# msp430g2452 register map
Registers from a debugger description file.
Registers are 8-bit, access not given, no defined reset value unless marked. A register's access mark holds for its fields unless they carry their own. Addresses are absolute; registers are grouped by the start of their names; lines under a group give offsets from that group; [hi:lo] are bit positions; {n}, {i} and the like mark numbered series; 'fields as' and 'values as' point back to an identical list; <NAME> marks a mode.

## SFR
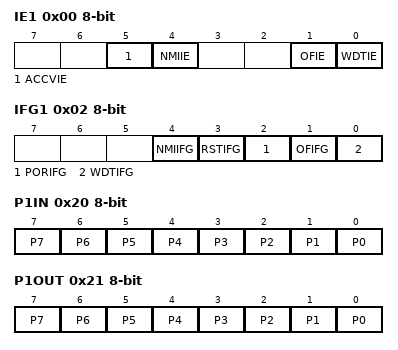
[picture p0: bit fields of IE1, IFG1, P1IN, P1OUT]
0x00 IE1
  [5] ACCVIE, [4] NMIIE, [1] OFIE, [0] WDTIE
0x02 IFG1
  [4] NMIIFG, [3] RSTIFG, [2] PORIFG, [1] OFIFG, [0] WDTIFG
0x20 P1IN
  [n] P{n} (n=0..7)
0x21 P1OUT
  [n] P{n} (n=0..7)
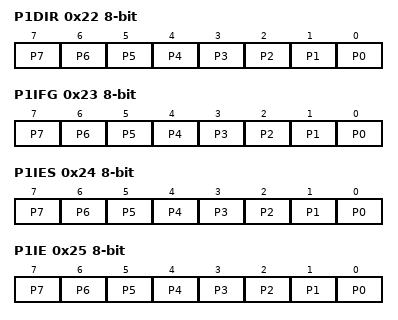
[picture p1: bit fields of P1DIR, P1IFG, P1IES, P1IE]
0x22 P1DIR
  [n] P{n} (n=0..7)
0x23 P1IFG
  [n] P{n} (n=0..7)
0x24 P1IES
  [n] P{n} (n=0..7)
0x25 P1IE
  [n] P{n} (n=0..7)
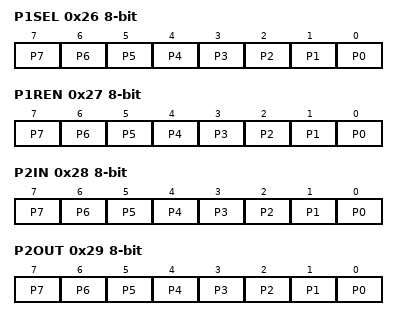
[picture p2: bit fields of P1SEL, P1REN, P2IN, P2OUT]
0x26 P1SEL
  [n] P{n} (n=0..7)
0x27 P1REN
  [n] P{n} (n=0..7)
0x28 P2IN
  [n] P{n} (n=0..7)
0x29 P2OUT
  [n] P{n} (n=0..7)
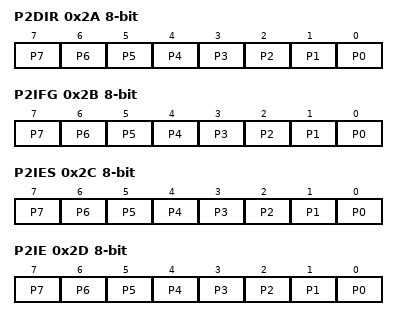
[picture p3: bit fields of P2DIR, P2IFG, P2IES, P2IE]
0x2A P2DIR
  [n] P{n} (n=0..7)
0x2B P2IFG
  [n] P{n} (n=0..7)
0x2C P2IES
  [n] P{n} (n=0..7)
0x2D P2IE
  [n] P{n} (n=0..7)
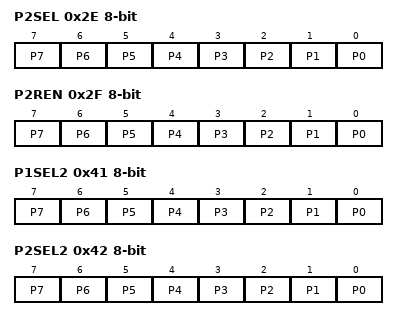
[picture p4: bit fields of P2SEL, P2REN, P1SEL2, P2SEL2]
0x2E P2SEL
  [n] P{n} (n=0..7)
0x2F P2REN
  [n] P{n} (n=0..7)
0x41 P1SEL2
  [n] P{n} (n=0..7)
0x42 P2SEL2
  [n] P{n} (n=0..7)
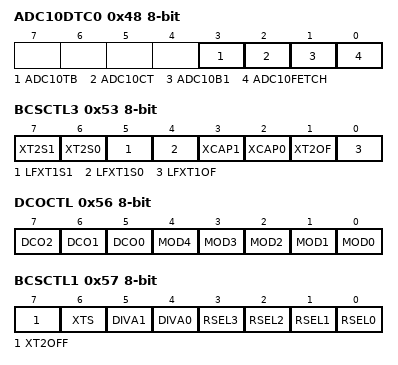
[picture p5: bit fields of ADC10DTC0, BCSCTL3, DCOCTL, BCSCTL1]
0x48 ADC10DTC0
  [3] ADC10TB, [2] ADC10CT, [1] ADC10B1, [0] ADC10FETCH
0x49 ADC10DTC1
0x4A ADC10AE0
0x53 BCSCTL3
  [7] XT2S1, [6] XT2S0, [5] LFXT1S1, [4] LFXT1S0, [3] XCAP1, [2] XCAP0, [1] XT2OF, [0] LFXT1OF
0x56 DCOCTL
  [7] DCO2, [6] DCO1, [5] DCO0, [n] MOD{n} (n=0..4)
0x57 BCSCTL1
  [7] XT2OFF, [6] XTS, [5] DIVA1, [4] DIVA0, [n] RSEL{n} (n=0..3)
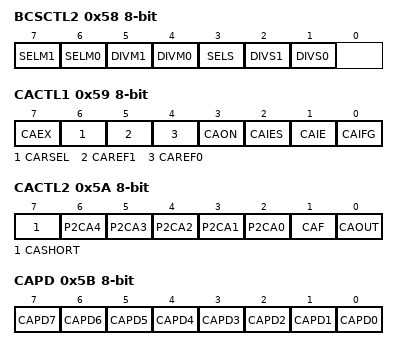
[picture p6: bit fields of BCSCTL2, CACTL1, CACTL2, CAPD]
0x58 BCSCTL2
  [7] SELM1, [6] SELM0, [5] DIVM1, [4] DIVM0, [3] SELS, [2] DIVS1, [1] DIVS0
0x59 CACTL1
  [7] CAEX, [6] CARSEL, [5] CAREF1, [4] CAREF0, [3] CAON, [2] CAIES, [1] CAIE, [0] CAIFG
0x5A CACTL2
  [7] CASHORT, [n+2] P2CA{n} (n=0..4), [1] CAF, [0] CAOUT
0x5B CAPD
  [n] CAPD{n} (n=0..7)
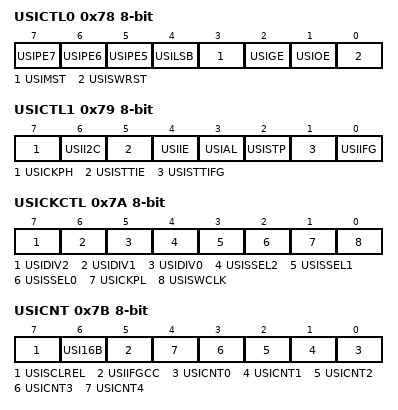
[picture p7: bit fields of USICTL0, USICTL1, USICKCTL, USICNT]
0x78 USICTL0
  [7] USIPE7, [6] USIPE6, [5] USIPE5, [4] USILSB, [3] USIMST, [2] USIGE, [1] USIOE, [0] USISWRST
0x78 USICTL 16-bit
0x79 USICTL1
  [7] USICKPH, [6] USII2C, [5] USISTTIE, [4] USIIE, [3] USIAL, [2] USISTP, [1] USISTTIFG, [0] USIIFG
0x7A USICKCTL
  [7] USIDIV2, [6] USIDIV1, [5] USIDIV0, [4] USISSEL2, [3] USISSEL1, [2] USISSEL0, [1] USICKPL, [0] USISWCLK
0x7A USICCTL 16-bit
0x7B USICNT
  [7] USISCLREL, [6] USI16B, [5] USIIFGCC, [n] USICNT{n} (n=0..4)
0x7C USISRL
0x7C USISR 16-bit
0x7D USISRH
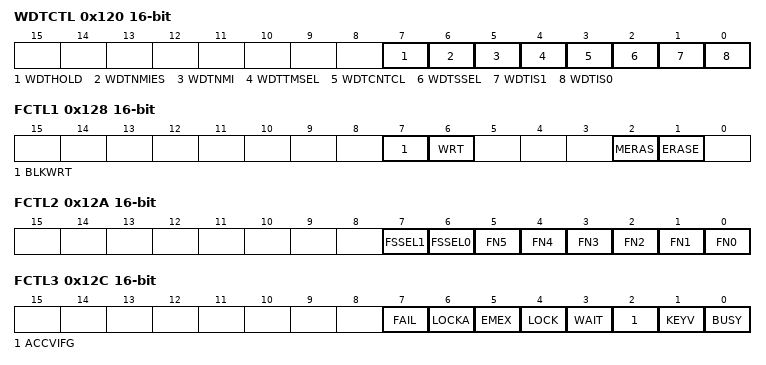
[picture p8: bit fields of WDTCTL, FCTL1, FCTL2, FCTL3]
0x120 WDTCTL 16-bit
  [7] WDTHOLD, [6] WDTNMIES, [5] WDTNMI, [4] WDTTMSEL, [3] WDTCNTCL, [2] WDTSSEL, [1] WDTIS1, [0] WDTIS0
0x128 FCTL1 16-bit
  [7] BLKWRT, [6] WRT, [2] MERAS, [1] ERASE
0x12A FCTL2 16-bit
  [7] FSSEL1, [6] FSSEL0, [n] FN{n} (n=0..5)
0x12C FCTL3 16-bit
  [7] FAIL, [6] LOCKA, [5] EMEX, [4] LOCK, [3] WAIT, [2] ACCVIFG, [1] KEYV, [0] BUSY
0x12E TA0IV 16-bit
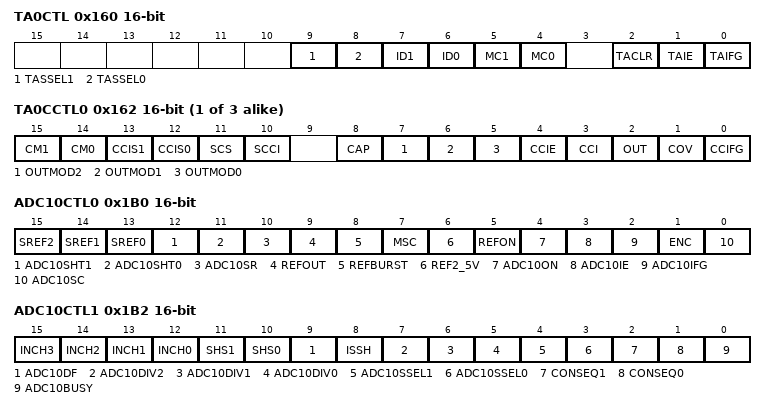
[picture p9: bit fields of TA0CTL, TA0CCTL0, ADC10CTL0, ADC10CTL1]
0x160 TA0CTL 16-bit
  [9] TASSEL1, [8] TASSEL0, [7] ID1, [6] ID0, [5] MC1, [4] MC0, [2] TACLR, [1] TAIE, [0] TAIFG
{0x162+2i} TA0CCTL{i} 16-bit (i=0..2)
  [15] CM1, [14] CM0, [13] CCIS1, [12] CCIS0, [11] SCS, [10] SCCI, [8] CAP, [7] OUTMOD2, [6] OUTMOD1, [5] OUTMOD0, [4] CCIE, [3] CCI, [2] OUT, [1] COV, [0] CCIFG
0x170 TA0R 16-bit
{0x172+2i} TA0CCR{i} 16-bit (i=0..2)
0x1B0 ADC10CTL0 16-bit
  [15] SREF2, [14] SREF1, [13] SREF0, [12] ADC10SHT1, [11] ADC10SHT0, [10] ADC10SR, [9] REFOUT, [8] REFBURST, [7] MSC, [6] REF2_5V, [5] REFON, [4] ADC10ON, [3] ADC10IE, [2] ADC10IFG, [1] ENC, [0] ADC10SC
0x1B2 ADC10CTL1 16-bit
  [n+12] INCH{n} (n=0..3), [11] SHS1, [10] SHS0, [9] ADC10DF, [8] ISSH, [7] ADC10DIV2, [6] ADC10DIV1, [5] ADC10DIV0, [4] ADC10SSEL1, [3] ADC10SSEL0, [2] CONSEQ1, [1] CONSEQ0, [0] ADC10BUSY
0x1B4 ADC10MEM 16-bit
0x1BC ADC10SA 16-bit

## CALDCO
0x10F8 CALDCO_16MHZ
0x10FA CALDCO_12MHZ
0x10FC CALDCO_8MHZ
0x10FE CALDCO_1MHZ

## CALBC1
0x10F9 CALBC1_16MHZ
0x10FB CALBC1_12MHZ
0x10FD CALBC1_8MHZ
0x10FF CALBC1_1MHZ

## Notices in the file
Copyright 1996-2003 Texas Instruments. All rights reserved.
